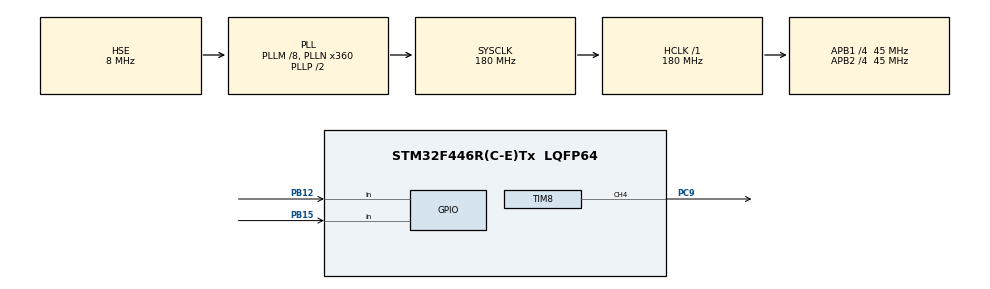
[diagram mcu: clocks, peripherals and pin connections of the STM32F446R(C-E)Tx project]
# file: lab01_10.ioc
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Mcu.Family=STM32F4
Mcu.Name=STM32F446R(C-E)Tx
Mcu.Package=LQFP64
NVIC.PriorityGroup=NVIC_PRIORITYGROUP_4
PA13.Mode=Serial_Wire
PA13.Signal=SYS_JTMS-SWDIO
PA14.Mode=Serial_Wire
PA14.Signal=SYS_JTCK-SWCLK
PB12.Signal=GPIO_Input
PB15.Signal=GPIO_Input
PC9.Signal=S_TIM8_CH4
PH0-OSC_IN.Mode=HSE-External-Oscillator
PH0-OSC_IN.Signal=RCC_OSC_IN
PH1-OSC_OUT.Mode=HSE-External-Oscillator
PH1-OSC_OUT.Signal=RCC_OSC_OUT
ProjectManager.HeapSize=0x200
ProjectManager.StackSize=0x400
ProjectManager.TargetToolchain=STM32CubeIDE
RCC.AHBFreq_Value=180000000
RCC.APB1CLKDivider=RCC_HCLK_DIV4
RCC.APB1Freq_Value=45000000
RCC.APB1TimFreq_Value=90000000
RCC.APB2CLKDivider=RCC_HCLK_DIV4
RCC.APB2Freq_Value=45000000
RCC.APB2TimFreq_Value=90000000
RCC.CortexFreq_Value=180000000
RCC.HCLKFreq_Value=180000000
RCC.HSE_VALUE=8000000
RCC.PLLM=8
RCC.PLLN=360
RCC.PLLSourceVirtual=RCC_PLLSOURCE_HSE
RCC.SYSCLKFreq_VALUE=180000000
RCC.SYSCLKSource=RCC_SYSCLKSOURCE_PLLCLK
RCC.USBFreq_Value=180000000
RCC.VCOOutputFreq_Value=360000000
SH.S_TIM8_CH4.0=TIM8_CH4,PWM Generation4 CH4
TIM8.AutoReloadPreload=TIM_AUTORELOAD_PRELOAD_ENABLE
TIM8.Channel-PWM\ Generation4\ CH4=TIM_CHANNEL_4
TIM8.Period=10000-1
TIM8.Prescaler=180-1
VP_TIM8_VS_ClockSourceINT.Mode=Internal
board=custom

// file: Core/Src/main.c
/* USER CODE BEGIN Header */
/**
  ******************************************************************************
  * @file           : main.c
  * @brief          : Main program body
  ******************************************************************************
  * @attention
  *
  * Copyright (c) 2026 STMicroelectronics.
  * All rights reserved.
  *
  * This software is licensed under terms that can be found in the LICENSE file
  * in the root directory of this software component.
  * If no LICENSE file comes with this software, it is provided AS-IS.
  *
  ******************************************************************************
  */
/* USER CODE END Header */
#include "main.h"

/* USER CODE BEGIN Includes */
#include <string.h>
/* USER CODE END Includes */

TIM_HandleTypeDef htim8;

/* USER CODE BEGIN PV */
//Button1-4
GPIO_TypeDef *buttonPort[4] = {GPIOB,GPIOB,GPIOB,GPIOB};
int button[4] = {GPIO_PIN_15,GPIO_PIN_12,GPIO_PIN_13,GPIO_PIN_14};

int servo1 = 50;		//Center at 50%
/* USER CODE END PV */

void SystemClock_Config(void);
static void MX_GPIO_Init(void);
static void MX_TIM8_Init(void);
/* USER CODE BEGIN PFP */
int isButtonPressed(int bt);
void setPWM(TIM_HandleTypeDef *timer, uint32_t channel,uint16_t pulse);
void stopPWM(TIM_HandleTypeDef *timer,uint32_t channel);
/* USER CODE END PFP */

int main(void)
{

  /* MCU Configuration--------------------------------------------------------*/

  /* Reset of all peripherals, Initializes the Flash interface and the Systick. */
  HAL_Init();

  /* Configure the system clock */
  SystemClock_Config();

  /* Initialize all configured peripherals */
  MX_GPIO_Init();
  MX_TIM8_Init();
  /* USER CODE BEGIN 2 */
  setPWM(&htim8,TIM_CHANNEL_4,servo1*5+500); // Center
  /* USER CODE END 2 */

  /* Infinite loop */
  /* USER CODE BEGIN WHILE */
  while (1)
  {
	  if(isButtonPressed(0)){
		  if(servo1>0) {servo1 --;}
	  }else if(isButtonPressed(1)){
		  if(servo1<100) {servo1 ++;}
	  }
	  TIM8->CCR4 = servo1*5+500;
    /* USER CODE END WHILE */

  }
}

void SystemClock_Config(void)
{
  RCC_OscInitTypeDef RCC_OscInitStruct = {0};
  RCC_ClkInitTypeDef RCC_ClkInitStruct = {0};

  /** Configure the main internal regulator output voltage
  */
  __HAL_RCC_PWR_CLK_ENABLE();
  __HAL_PWR_VOLTAGESCALING_CONFIG(PWR_REGULATOR_VOLTAGE_SCALE1);

  /** Initializes the RCC Oscillators according to the specified parameters
  * in the RCC_OscInitTypeDef structure.
  */
  RCC_OscInitStruct.OscillatorType = RCC_OSCILLATORTYPE_HSE;
  RCC_OscInitStruct.HSEState = RCC_HSE_ON;
  RCC_OscInitStruct.PLL.PLLState = RCC_PLL_ON;
  RCC_OscInitStruct.PLL.PLLSource = RCC_PLLSOURCE_HSE;
  RCC_OscInitStruct.PLL.PLLM = 8;
  RCC_OscInitStruct.PLL.PLLN = 360;
  RCC_OscInitStruct.PLL.PLLP = RCC_PLLP_DIV2;
  RCC_OscInitStruct.PLL.PLLQ = 2;
  RCC_OscInitStruct.PLL.PLLR = 2;
  if (HAL_RCC_OscConfig(&RCC_OscInitStruct) != HAL_OK)
  {
    Error_Handler();
  }

  /** Activate the Over-Drive mode
  */
  if (HAL_PWREx_EnableOverDrive() != HAL_OK)
  {
    Error_Handler();
  }

  /** Initializes the CPU, AHB and APB buses clocks
  */
  RCC_ClkInitStruct.ClockType = RCC_CLOCKTYPE_HCLK|RCC_CLOCKTYPE_SYSCLK
                              |RCC_CLOCKTYPE_PCLK1|RCC_CLOCKTYPE_PCLK2;
  RCC_ClkInitStruct.SYSCLKSource = RCC_SYSCLKSOURCE_PLLCLK;
  RCC_ClkInitStruct.AHBCLKDivider = RCC_SYSCLK_DIV1;
  RCC_ClkInitStruct.APB1CLKDivider = RCC_HCLK_DIV4;
  RCC_ClkInitStruct.APB2CLKDivider = RCC_HCLK_DIV4;

  if (HAL_RCC_ClockConfig(&RCC_ClkInitStruct, FLASH_LATENCY_5) != HAL_OK)
  {
    Error_Handler();
  }
}

static void MX_TIM8_Init(void)
{

  TIM_ClockConfigTypeDef sClockSourceConfig = {0};
  TIM_MasterConfigTypeDef sMasterConfig = {0};
  TIM_OC_InitTypeDef sConfigOC = {0};
  TIM_BreakDeadTimeConfigTypeDef sBreakDeadTimeConfig = {0};

  htim8.Instance = TIM8;
  htim8.Init.Prescaler = 180-1;
  htim8.Init.CounterMode = TIM_COUNTERMODE_UP;
  htim8.Init.Period = 10000-1;
  htim8.Init.ClockDivision = TIM_CLOCKDIVISION_DIV1;
  htim8.Init.RepetitionCounter = 0;
  htim8.Init.AutoReloadPreload = TIM_AUTORELOAD_PRELOAD_ENABLE;
  if (HAL_TIM_Base_Init(&htim8) != HAL_OK)
  {
    Error_Handler();
  }
  sClockSourceConfig.ClockSource = TIM_CLOCKSOURCE_INTERNAL;
  if (HAL_TIM_ConfigClockSource(&htim8, &sClockSourceConfig) != HAL_OK)
  {
    Error_Handler();
  }
  if (HAL_TIM_PWM_Init(&htim8) != HAL_OK)
  {
    Error_Handler();
  }
  sMasterConfig.MasterOutputTrigger = TIM_TRGO_RESET;
  sMasterConfig.MasterSlaveMode = TIM_MASTERSLAVEMODE_DISABLE;
  if (HAL_TIMEx_MasterConfigSynchronization(&htim8, &sMasterConfig) != HAL_OK)
  {
    Error_Handler();
  }
  sConfigOC.OCMode = TIM_OCMODE_PWM1;
  sConfigOC.Pulse = 0;
  sConfigOC.OCPolarity = TIM_OCPOLARITY_HIGH;
  sConfigOC.OCFastMode = TIM_OCFAST_DISABLE;
  sConfigOC.OCIdleState = TIM_OCIDLESTATE_RESET;
  sConfigOC.OCNIdleState = TIM_OCNIDLESTATE_RESET;
  if (HAL_TIM_PWM_ConfigChannel(&htim8, &sConfigOC, TIM_CHANNEL_4) != HAL_OK)
  {
    Error_Handler();
  }
  sBreakDeadTimeConfig.OffStateRunMode = TIM_OSSR_DISABLE;
  sBreakDeadTimeConfig.OffStateIDLEMode = TIM_OSSI_DISABLE;
  sBreakDeadTimeConfig.LockLevel = TIM_LOCKLEVEL_OFF;
  sBreakDeadTimeConfig.DeadTime = 0;
  sBreakDeadTimeConfig.BreakState = TIM_BREAK_DISABLE;
  sBreakDeadTimeConfig.BreakPolarity = TIM_BREAKPOLARITY_HIGH;
  sBreakDeadTimeConfig.AutomaticOutput = TIM_AUTOMATICOUTPUT_DISABLE;
  if (HAL_TIMEx_ConfigBreakDeadTime(&htim8, &sBreakDeadTimeConfig) != HAL_OK)
  {
    Error_Handler();
  }
  HAL_TIM_MspPostInit(&htim8);

}

static void MX_GPIO_Init(void)
{
  GPIO_InitTypeDef GPIO_InitStruct = {0};

  /* GPIO Ports Clock Enable */
  __HAL_RCC_GPIOH_CLK_ENABLE();
  __HAL_RCC_GPIOB_CLK_ENABLE();
  __HAL_RCC_GPIOC_CLK_ENABLE();
  __HAL_RCC_GPIOA_CLK_ENABLE();

  /*Configure GPIO pins : PB12 PB15 */
  GPIO_InitStruct.Pin = GPIO_PIN_12|GPIO_PIN_15;
  GPIO_InitStruct.Mode = GPIO_MODE_INPUT;
  GPIO_InitStruct.Pull = GPIO_NOPULL;
  HAL_GPIO_Init(GPIOB, &GPIO_InitStruct);

}

/* USER CODE BEGIN 4 */
int isButtonPressed(int bt){
	// This version does not wait for button to depressed
	int x1=HAL_GPIO_ReadPin(buttonPort[bt&3],button[bt&3]);
	HAL_Delay(10);  //Delay for a bit to check for debouncing
	int x2=HAL_GPIO_ReadPin(buttonPort[bt&3],button[bt&3]);
	if((x1==x2)&&(x2==0)){
		return 1;
	}
	return 0;
}

void setPWM(TIM_HandleTypeDef *timer, uint32_t channel, uint16_t pulse){
	HAL_TIM_PWM_Stop(timer,channel);
	TIM_OC_InitTypeDef sConfigOC;

	memset((void *)&sConfigOC,0,sizeof(sConfigOC));

	sConfigOC.OCMode = TIM_OCMODE_PWM1;
	sConfigOC.Pulse = pulse;
	sConfigOC.OCPolarity = TIM_OCPOLARITY_HIGH;
	sConfigOC.OCFastMode = TIM_OCFAST_DISABLE;
	HAL_TIM_PWM_ConfigChannel(timer, &sConfigOC, channel);
	HAL_TIM_PWM_Start(timer, channel);
}

void stopPWM(TIM_HandleTypeDef *timer,uint32_t channel){
	HAL_TIM_PWM_Stop(timer,channel);
	TIM_OC_InitTypeDef sConfigOC;

	memset((void *)&sConfigOC,0,sizeof(sConfigOC));

	sConfigOC.OCMode = TIM_OCMODE_PWM1;
	sConfigOC.Pulse = 0;
	sConfigOC.OCPolarity = TIM_OCPOLARITY_HIGH;
	sConfigOC.OCFastMode = TIM_OCFAST_DISABLE;
	HAL_TIM_PWM_ConfigChannel(timer, &sConfigOC, channel);
}
/* USER CODE END 4 */

void Error_Handler(void)
{
  __disable_irq();
  while (1)
  {
  }
}
